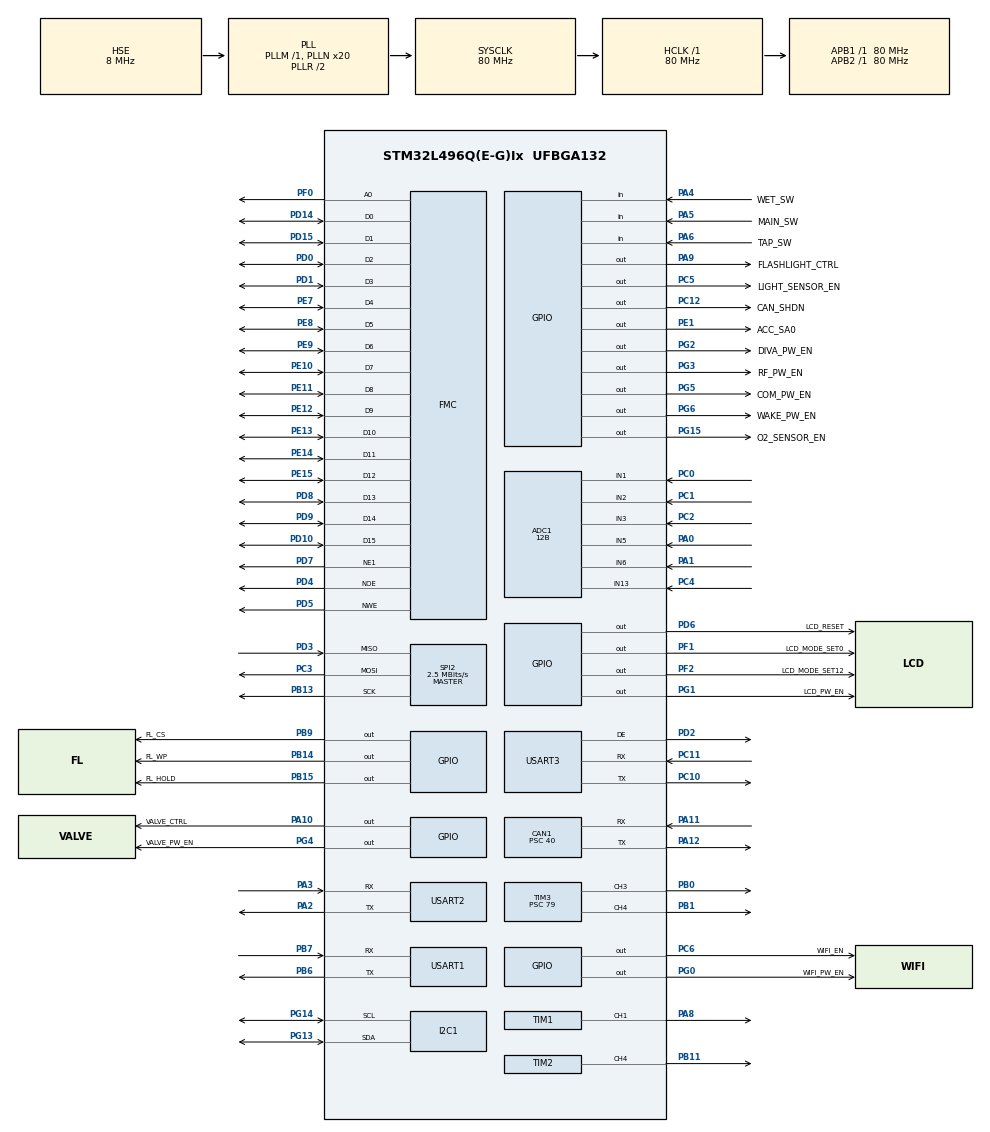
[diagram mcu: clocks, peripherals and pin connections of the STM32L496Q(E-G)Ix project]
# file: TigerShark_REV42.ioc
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ADC1.Channel-0\#ChannelRegularConversion=ADC_CHANNEL_1
ADC1.Channel-1\#ChannelRegularConversion=ADC_CHANNEL_2
ADC1.Channel-2\#ChannelRegularConversion=ADC_CHANNEL_3
ADC1.Channel-3\#ChannelRegularConversion=ADC_CHANNEL_5
ADC1.Channel-4\#ChannelRegularConversion=ADC_CHANNEL_6
ADC1.Channel-5\#ChannelRegularConversion=ADC_CHANNEL_13
ADC1.Channel-6\#ChannelRegularConversion=ADC_CHANNEL_VREFINT
ADC1.ClockPrescaler=ADC_CLOCK_ASYNC_DIV1
ADC1.ContinuousConvMode=DISABLE
ADC1.DMAContinuousRequests=ENABLE
ADC1.DataAlign=ADC_DATAALIGN_RIGHT
ADC1.EOCSelection=ADC_EOC_SINGLE_CONV
ADC1.ExternalTrigConv=ADC_EXTERNALTRIG_T4_TRGO
ADC1.NbrOfConversion=7
ADC1.NbrOfConversionFlag=1
ADC1.OffsetNumber-0\#ChannelRegularConversion=ADC_OFFSET_NONE
ADC1.OffsetNumber-1\#ChannelRegularConversion=ADC_OFFSET_NONE
ADC1.OffsetNumber-2\#ChannelRegularConversion=ADC_OFFSET_NONE
ADC1.OffsetNumber-3\#ChannelRegularConversion=ADC_OFFSET_NONE
ADC1.OffsetNumber-4\#ChannelRegularConversion=ADC_OFFSET_NONE
ADC1.OffsetNumber-5\#ChannelRegularConversion=ADC_OFFSET_NONE
ADC1.OffsetNumber-6\#ChannelRegularConversion=ADC_OFFSET_NONE
ADC1.OversamplingMode=DISABLE
ADC1.Rank-0\#ChannelRegularConversion=1
ADC1.Rank-1\#ChannelRegularConversion=2
ADC1.Rank-2\#ChannelRegularConversion=3
ADC1.Rank-3\#ChannelRegularConversion=4
ADC1.Rank-4\#ChannelRegularConversion=5
ADC1.Rank-5\#ChannelRegularConversion=6
ADC1.Rank-6\#ChannelRegularConversion=7
ADC1.Resolution=ADC_RESOLUTION_12B
ADC1.SamplingTime-0\#ChannelRegularConversion=ADC_SAMPLETIME_92CYCLES_5
ADC1.SamplingTime-1\#ChannelRegularConversion=ADC_SAMPLETIME_92CYCLES_5
ADC1.SamplingTime-2\#ChannelRegularConversion=ADC_SAMPLETIME_92CYCLES_5
ADC1.SamplingTime-3\#ChannelRegularConversion=ADC_SAMPLETIME_92CYCLES_5
ADC1.SamplingTime-4\#ChannelRegularConversion=ADC_SAMPLETIME_92CYCLES_5
ADC1.SamplingTime-5\#ChannelRegularConversion=ADC_SAMPLETIME_92CYCLES_5
ADC1.SamplingTime-6\#ChannelRegularConversion=ADC_SAMPLETIME_92CYCLES_5
ADC1.master=1
CAN1.BS1=CAN_BS1_13TQ
CAN1.BS2=CAN_BS2_2TQ
CAN1.CalculateBaudRate=125000
CAN1.CalculateTimeBit=8000
CAN1.CalculateTimeQuantum=500.0
CAN1.Prescaler=40
CAN1.SJW=CAN_SJW_4TQ
Dma.ADC1.0.Direction=DMA_PERIPH_TO_MEMORY
Dma.ADC1.0.Instance=DMA1_Channel1
Dma.ADC1.0.MemDataAlignment=DMA_MDATAALIGN_HALFWORD
Dma.ADC1.0.MemInc=DMA_MINC_ENABLE
Dma.ADC1.0.Mode=DMA_CIRCULAR
Dma.ADC1.0.PeriphDataAlignment=DMA_PDATAALIGN_HALFWORD
Dma.ADC1.0.PeriphInc=DMA_PINC_DISABLE
Dma.ADC1.0.Priority=DMA_PRIORITY_LOW
Dma.Request0=ADC1
FMC.AddressSetupTime1=0
FMC.BusTurnAroundDuration1=3
FMC.DataSetupTime1=1
FREERTOS.Tasks01=defaultTask,24,128,StartDefaultTask,Default,NULL,Dynamic,NULL,NULL
FREERTOS.configTOTAL_HEAP_SIZE=65535
FREERTOS.configUSE_NEWLIB_REENTRANT=1
I2C1.Speed=100
I2C1.Timing=0x10D19CE4
Mcu.Family=STM32L4
Mcu.Name=STM32L496Q(E-G)Ix
Mcu.Package=UFBGA132
NVIC.ADC1_2_IRQn=true\:5\:0\:true\:false\:true\:true\:true\:true\:true
NVIC.CAN1_RX0_IRQn=true\:5\:0\:true\:false\:true\:true\:true\:true\:true
NVIC.CAN1_RX1_IRQn=true\:5\:0\:true\:false\:true\:true\:true\:true\:true
NVIC.DMA1_Channel1_IRQn=true\:5\:0\:false\:false\:true\:true\:false\:true\:true
NVIC.PriorityGroup=NVIC_PRIORITYGROUP_4
NVIC.TIM1_TRG_COM_TIM17_IRQn=true\:5\:0\:false\:false\:true\:true\:true\:true\:true
NVIC.TIM1_UP_TIM16_IRQn=true\:15\:0\:false\:false\:true\:false\:false\:true\:true
NVIC.TIM6_DAC_IRQn=true\:5\:0\:false\:false\:true\:true\:true\:true\:true
NVIC.TimeBase=TIM1_UP_TIM16_IRQn
NVIC.TimeBaseIP=TIM16
NVIC.USART1_IRQn=true\:5\:0\:false\:false\:true\:true\:true\:true\:true
NVIC.USART2_IRQn=true\:5\:0\:false\:false\:true\:true\:true\:true\:true
PA0.Signal=ADCx_IN5
PA1.Signal=ADCx_IN6
PA10.GPIO_Label=VALVE_CTRL
PA10.GPIO_ModeDefaultOutputPP=GPIO_MODE_OUTPUT_PP
PA10.GPIO_PuPd=GPIO_PULLUP
PA10.GPIO_Speed=GPIO_SPEED_FREQ_VERY_HIGH
PA10.PinState=GPIO_PIN_SET
PA10.Signal=GPIO_Output
PA11.Mode=CAN_Activate
PA11.Signal=CAN1_RX
PA12.Mode=CAN_Activate
PA12.Signal=CAN1_TX
PA13\ (JTMS/SWDIO).Mode=Serial_Wire
PA13\ (JTMS/SWDIO).Signal=SYS_JTMS-SWDIO
PA14\ (JTCK/SWCLK).Mode=Serial_Wire
PA14\ (JTCK/SWCLK).Signal=SYS_JTCK-SWCLK
PA2.Mode=Asynchronous
PA2.Signal=USART2_TX
PA3.Mode=Asynchronous
PA3.Signal=USART2_RX
PA4.GPIO_Label=WET_SW
PA4.GPIO_PuPd=GPIO_NOPULL
PA4.Signal=GPIO_Input
PA5.GPIO_Label=MAIN_SW
PA5.GPIO_PuPd=GPIO_NOPULL
PA5.Signal=GPIO_Input
PA6.GPIO_Label=TAP_SW
PA6.GPIO_PuPd=GPIO_NOPULL
PA6.Signal=GPIO_Input
PA8.Signal=S_TIM1_CH1
PA9.GPIO_Label=FLASHLIGHT_CTRL
PA9.Signal=GPIO_Output
PB0.Signal=S_TIM3_CH3
PB1.Signal=S_TIM3_CH4
PB11.Signal=S_TIM2_CH4
PB13.Mode=Full_Duplex_Master
PB13.Signal=SPI2_SCK
PB14.GPIO_Label=FL_WP
PB14.GPIO_ModeDefaultOutputPP=GPIO_MODE_OUTPUT_PP
PB14.GPIO_PuPd=GPIO_PULLUP
PB14.GPIO_Speed=GPIO_SPEED_FREQ_LOW
PB14.PinState=GPIO_PIN_SET
PB14.Signal=GPIO_Output
PB15.GPIO_Label=FL_HOLD
PB15.GPIO_ModeDefaultOutputPP=GPIO_MODE_OUTPUT_PP
PB15.GPIO_PuPd=GPIO_PULLUP
PB15.PinState=GPIO_PIN_SET
PB15.Signal=GPIO_Output
PB6.Mode=Asynchronous
PB6.Signal=USART1_TX
PB7.Mode=Asynchronous
PB7.Signal=USART1_RX
PB9.GPIO_Label=FL_CS
PB9.GPIO_ModeDefaultOutputPP=GPIO_MODE_OUTPUT_PP
PB9.GPIO_PuPd=GPIO_PULLUP
PB9.GPIO_Speed=GPIO_SPEED_FREQ_LOW
PB9.PinState=GPIO_PIN_SET
PB9.Signal=GPIO_Output
PC0.Signal=ADCx_IN1
PC1.Signal=ADCx_IN2
PC10.Mode=Asynchronous
PC10.Signal=USART3_TX
PC11.Mode=Asynchronous
PC11.Signal=USART3_RX
PC12.GPIO_Label=CAN_SHDN
PC12.GPIO_ModeDefaultOutputPP=GPIO_MODE_OUTPUT_PP
PC12.GPIO_PuPd=GPIO_PULLUP
PC12.Signal=GPIO_Output
PC14-OSC32_IN\ (PC14).Mode=LSE-External-Oscillator
PC14-OSC32_IN\ (PC14).Signal=RCC_OSC32_IN
PC15-OSC32_OUT\ (PC15).Mode=LSE-External-Oscillator
PC15-OSC32_OUT\ (PC15).Signal=RCC_OSC32_OUT
PC2.Signal=ADCx_IN3
PC3.Mode=Full_Duplex_Master
PC3.Signal=SPI2_MOSI
PC4.Signal=ADCx_IN13
PC5.GPIO_Label=LIGHT_SENSOR_EN
PC5.GPIO_PuPd=GPIO_PULLUP
PC5.Signal=GPIO_Output
PC6.GPIO_Label=WIFI_EN
PC6.GPIO_ModeDefaultOutputPP=GPIO_MODE_OUTPUT_PP
PC6.GPIO_PuPd=GPIO_PULLUP
PC6.Signal=GPIO_Output
PD0.Signal=FMC_D2_DA2
PD1.Signal=FMC_D3_DA3
PD10.Signal=FMC_D15_DA15
PD14.Signal=FMC_D0_DA0
PD15.Signal=FMC_D1_DA1
PD2.Mode=Hardware Flow Control (RS485)
PD2.Signal=USART3_DE
PD3.Mode=Full_Duplex_Master
PD3.Signal=SPI2_MISO
PD4.Signal=FMC_NOE
PD5.Signal=FMC_NWE
PD6.GPIO_Label=LCD_RESET
PD6.GPIO_PuPd=GPIO_PULLUP
PD6.PinState=GPIO_PIN_SET
PD6.Signal=GPIO_Output
PD7.Mode=NorPsramChipSelect1_1
PD7.Signal=FMC_NE1
PD8.Signal=FMC_D13_DA13
PD9.Signal=FMC_D14_DA14
PE1.GPIO_Label=ACC_SA0
PE1.GPIO_PuPd=GPIO_PULLUP
PE1.Signal=GPIO_Output
PE10.Signal=FMC_D7_DA7
PE11.Signal=FMC_D8_DA8
PE12.Signal=FMC_D9_DA9
PE13.Signal=FMC_D10_DA10
PE14.Signal=FMC_D11_DA11
PE15.Signal=FMC_D12_DA12
PE7.Signal=FMC_D4_DA4
PE8.Signal=FMC_D5_DA5
PE9.Signal=FMC_D6_DA6
PF0.Signal=FMC_A0
PF1.GPIO_Label=LCD_MODE_SET0
PF1.GPIO_ModeDefaultOutputPP=GPIO_MODE_OUTPUT_PP
PF1.GPIO_PuPd=GPIO_PULLUP
PF1.PinState=GPIO_PIN_SET
PF1.Signal=GPIO_Output
PF2.GPIO_Label=LCD_MODE_SET12
PF2.GPIO_PuPd=GPIO_PULLDOWN
PF2.Signal=GPIO_Output
PG0.GPIO_Label=WIFI_PW_EN
PG0.Signal=GPIO_Output
PG1.GPIO_Label=LCD_PW_EN
PG1.Signal=GPIO_Output
PG13.Mode=I2C
PG13.Signal=I2C1_SDA
PG14.Mode=I2C
PG14.Signal=I2C1_SCL
PG15.GPIO_Label=O2_SENSOR_EN
PG15.Signal=GPIO_Output
PG2.GPIO_Label=DIVA_PW_EN
PG2.Signal=GPIO_Output
PG3.GPIO_Label=RF_PW_EN
PG3.Signal=GPIO_Output
PG4.GPIO_Label=VALVE_PW_EN
PG4.Signal=GPIO_Output
PG5.GPIO_Label=COM_PW_EN
PG5.Signal=GPIO_Output
PG6.GPIO_Label=WAKE_PW_EN
PG6.Signal=GPIO_Output
PH0-OSC_IN\ (PH0).Mode=HSE-External-Oscillator
PH0-OSC_IN\ (PH0).Signal=RCC_OSC_IN
PH1-OSC_OUT\ (PH1).Mode=HSE-External-Oscillator
PH1-OSC_OUT\ (PH1).Signal=RCC_OSC_OUT
ProjectManager.HeapSize=0x400
ProjectManager.StackSize=0x1024
ProjectManager.TargetToolchain=STM32CubeIDE
RCC.ADCFreq_Value=32000000
RCC.AHBFreq_Value=80000000
RCC.APB1Freq_Value=80000000
RCC.APB1TimFreq_Value=80000000
RCC.APB2Freq_Value=80000000
RCC.APB2TimFreq_Value=80000000
RCC.CortexFreq_Value=80000000
RCC.HCLKFreq_Value=80000000
RCC.HSE_VALUE=8000000
RCC.HSI48_VALUE=48000000
RCC.HSI_VALUE=16000000
RCC.MSI_VALUE=4000000
RCC.PLLN=20
RCC.PLLSourceVirtual=RCC_PLLSOURCE_HSE
RCC.RTCClockSelection=RCC_RTCCLKSOURCE_LSE
RCC.SYSCLKFreq_VALUE=80000000
RCC.SYSCLKSource=RCC_SYSCLKSOURCE_PLLCLK
RCC.USBFreq_Value=32000000
RCC.VCOOutputFreq_Value=160000000
RTC.Date=1
RTC.Month=RTC_MONTH_JANUARY
RTC.Year=0
SH.ADCx_IN1.0=ADC1_IN1,IN1-Single-Ended
SH.ADCx_IN13.0=ADC1_IN13,IN13-Single-Ended
SH.ADCx_IN2.0=ADC1_IN2,IN2-Single-Ended
SH.ADCx_IN3.0=ADC1_IN3,IN3-Single-Ended
SH.ADCx_IN5.0=ADC1_IN5,IN5-Single-Ended
SH.ADCx_IN6.0=ADC1_IN6,IN6-Single-Ended
SH.FMC_A0.0=FMC_A0,A0_1
SH.FMC_D0_DA0.0=FMC_D0,16b-d1
SH.FMC_D10_DA10.0=FMC_D10,16b-d1
SH.FMC_D11_DA11.0=FMC_D11,16b-d1
SH.FMC_D12_DA12.0=FMC_D12,16b-d1
SH.FMC_D13_DA13.0=FMC_D13,16b-d1
SH.FMC_D14_DA14.0=FMC_D14,16b-d1
SH.FMC_D15_DA15.0=FMC_D15,16b-d1
SH.FMC_D1_DA1.0=FMC_D1,16b-d1
SH.FMC_D2_DA2.0=FMC_D2,16b-d1
SH.FMC_D3_DA3.0=FMC_D3,16b-d1
SH.FMC_D4_DA4.0=FMC_D4,16b-d1
SH.FMC_D5_DA5.0=FMC_D5,16b-d1
SH.FMC_D6_DA6.0=FMC_D6,16b-d1
SH.FMC_D7_DA7.0=FMC_D7,16b-d1
SH.FMC_D8_DA8.0=FMC_D8,16b-d1
SH.FMC_D9_DA9.0=FMC_D9,16b-d1
SH.FMC_NOE.0=FMC_NOE,Lcd1
SH.FMC_NWE.0=FMC_NWE,Lcd1
SH.S_TIM1_CH1.0=TIM1_CH1,PWM Generation1 CH1
SH.S_TIM2_CH4.0=TIM2_CH4,PWM Generation4 CH4
SH.S_TIM3_CH3.0=TIM3_CH3,PWM Generation3 CH3
SH.S_TIM3_CH4.0=TIM3_CH4,PWM Generation4 CH4
SPI2.BaudRatePrescaler=SPI_BAUDRATEPRESCALER_32
SPI2.CalculateBaudRate=2.5 MBits/s
SPI2.DataSize=SPI_DATASIZE_8BIT
SPI2.Direction=SPI_DIRECTION_2LINES
SPI2.Mode=SPI_MODE_MASTER
SPI2.VirtualType=VM_MASTER
TIM1.Channel-PWM\ Generation1\ CH1=TIM_CHANNEL_1
TIM1.Period=499
TIM1.Prescaler=79
TIM1.Pulse-PWM\ Generation1\ CH1=100
TIM2.Channel-PWM\ Generation4\ CH4=TIM_CHANNEL_4
TIM2.OCPolarity_4=TIM_OCPOLARITY_HIGH
TIM2.Period=1000
TIM2.Prescaler=79
TIM3.Channel-PWM\ Generation3\ CH3=TIM_CHANNEL_3
TIM3.Channel-PWM\ Generation4\ CH4=TIM_CHANNEL_4
TIM3.OCMode_PWM-PWM\ Generation4\ CH4=TIM_OCMODE_PWM1
TIM3.OCPolarity_3=TIM_OCPOLARITY_HIGH
TIM3.OCPolarity_4=TIM_OCPOLARITY_HIGH
TIM3.Period=1000
TIM3.Prescaler=79
TIM3.Pulse-PWM\ Generation3\ CH3=0
TIM3.Pulse-PWM\ Generation4\ CH4=0
TIM4.Channel-Output\ Compare1\ No\ Output=TIM_CHANNEL_1
TIM4.Period=625
TIM4.Prescaler=79
TIM4.TIM_MasterOutputTrigger=TIM_TRGO_UPDATE
TIM6.AutoReloadPreload=TIM_AUTORELOAD_PRELOAD_ENABLE
TIM6.Period=7999
TIM6.Prescaler=9999
USART1.VirtualMode-Asynchronous=VM_ASYNC
USART2.Parity=PARITY_NONE
USART2.VirtualMode-Asynchronous=VM_ASYNC
USART2.WordLength=WORDLENGTH_8B
USART3.VirtualMode-Asynchronous=VM_ASYNC
USART3.VirtualMode-Hardware\ Flow\ Control\ (RS485)=VM_ASYNC
VP_ADC1_Vref_Input.Mode=IN-Vrefint
VP_FREERTOS_VS_CMSIS_V2.Mode=CMSIS_V2
VP_RTC_VS_RTC_Activate.Mode=RTC_Enabled
VP_RTC_VS_RTC_Calendar.Mode=RTC_Calendar
VP_SYS_VS_tim16.Mode=TIM16
VP_TIM3_VS_ClockSourceINT.Mode=Internal
VP_TIM4_VS_no_output1.Mode=Output Compare1 No Output
VP_TIM6_VS_ClockSourceINT.Mode=Enable_Timer
board=custom

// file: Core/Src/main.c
/* USER CODE BEGIN Header */
/**
  ******************************************************************************
  * @file           : main.c
  * @brief          : Main program body
  ******************************************************************************
  * @attention
  *
  * Copyright (c) 2025 STMicroelectronics.
  * All rights reserved.
  *
  * This software is licensed under terms that can be found in the LICENSE file
  * in the root directory of this software component.
  * If no LICENSE file comes with this software, it is provided AS-IS.
  *
  ******************************************************************************
  */
/* USER CODE END Header */
#include "main.h"
#include "cmsis_os2.h"

/* USER CODE BEGIN Includes */
#include "app_main.h"
/* USER CODE END Includes */

/* USER CODE BEGIN PTD */
#define ETX_APP_FLASH_ADDR    (0x0800A000)
/* USER CODE END PTD */

ADC_HandleTypeDef hadc1;
DMA_HandleTypeDef hdma_adc1;

CAN_HandleTypeDef hcan1;

I2C_HandleTypeDef hi2c1;

RTC_HandleTypeDef hrtc;

SPI_HandleTypeDef hspi2;

TIM_HandleTypeDef htim1;
TIM_HandleTypeDef htim2;
TIM_HandleTypeDef htim3;
TIM_HandleTypeDef htim4;
TIM_HandleTypeDef htim6;

UART_HandleTypeDef huart1;
UART_HandleTypeDef huart2;
UART_HandleTypeDef huart3;

SRAM_HandleTypeDef hsram1;

/* Definitions for defaultTask */
osThreadId_t defaultTaskHandle;
const osThreadAttr_t defaultTask_attributes = {
  .name = "defaultTask",
  .stack_size = 128 * 4,
  .priority = (osPriority_t) osPriorityNormal,
};

void SystemClock_Config(void);
static void MX_GPIO_Init(void);
static void MX_DMA_Init(void);
static void MX_ADC1_Init(void);
static void MX_TIM3_Init(void);
static void MX_FMC_Init(void);
static void MX_I2C1_Init(void);
static void MX_SPI2_Init(void);
static void MX_TIM4_Init(void);
static void MX_TIM1_Init(void);
static void MX_TIM2_Init(void);
static void MX_USART3_UART_Init(void);
static void MX_CAN1_Init(void);
static void MX_USART2_UART_Init(void);
static void MX_USART1_UART_Init(void);
static void MX_TIM6_Init(void);
static void MX_RTC_Init(void);
void StartDefaultTask(void *argument);

int main(void)
{

  /* USER CODE BEGIN 1 */
  SCB->VTOR = (uint32_t) ETX_APP_FLASH_ADDR;
  /* USER CODE END 1 */

  /* MCU Configuration--------------------------------------------------------*/

  /* Reset of all peripherals, Initializes the Flash interface and the Systick. */
  HAL_Init();

  /* Configure the system clock */
  SystemClock_Config();

  /* Initialize all configured peripherals */
  MX_GPIO_Init();
  MX_DMA_Init();
  MX_ADC1_Init();
  MX_TIM3_Init();
  MX_FMC_Init();
  MX_I2C1_Init();
  MX_SPI2_Init();
  MX_TIM4_Init();
  MX_TIM1_Init();
  MX_TIM2_Init();
  MX_USART3_UART_Init();
  MX_CAN1_Init();
  MX_USART2_UART_Init();
  MX_USART1_UART_Init();
  MX_TIM6_Init();
  MX_RTC_Init();
  /* USER CODE BEGIN 2 */
  app_main_init();
  /* USER CODE END 2 */

  /* Init scheduler */
  osKernelInitialize();

  /* Create the thread(s) */
  /* creation of defaultTask */
  defaultTaskHandle = osThreadNew(StartDefaultTask, NULL, &defaultTask_attributes);

  /* Start scheduler */
  osKernelStart();

  /* We should never get here as control is now taken by the scheduler */

  /* Infinite loop */
  while (1)
  {

  }
}

void SystemClock_Config(void)
{
  RCC_OscInitTypeDef RCC_OscInitStruct = {0};
  RCC_ClkInitTypeDef RCC_ClkInitStruct = {0};

  /** Configure the main internal regulator output voltage
  */
  if (HAL_PWREx_ControlVoltageScaling(PWR_REGULATOR_VOLTAGE_SCALE1) != HAL_OK)
  {
    Error_Handler();
  }

  /** Configure LSE Drive Capability
  */
  HAL_PWR_EnableBkUpAccess();
  __HAL_RCC_LSEDRIVE_CONFIG(RCC_LSEDRIVE_LOW);

  /** Initializes the RCC Oscillators according to the specified parameters
  * in the RCC_OscInitTypeDef structure.
  */
  RCC_OscInitStruct.OscillatorType = RCC_OSCILLATORTYPE_HSE|RCC_OSCILLATORTYPE_LSE;
  RCC_OscInitStruct.HSEState = RCC_HSE_ON;
  RCC_OscInitStruct.LSEState = RCC_LSE_ON;
  RCC_OscInitStruct.PLL.PLLState = RCC_PLL_ON;
  RCC_OscInitStruct.PLL.PLLSource = RCC_PLLSOURCE_HSE;
  RCC_OscInitStruct.PLL.PLLM = 1;
  RCC_OscInitStruct.PLL.PLLN = 20;
  RCC_OscInitStruct.PLL.PLLP = RCC_PLLP_DIV2;
  RCC_OscInitStruct.PLL.PLLQ = RCC_PLLQ_DIV2;
  RCC_OscInitStruct.PLL.PLLR = RCC_PLLR_DIV2;
  if (HAL_RCC_OscConfig(&RCC_OscInitStruct) != HAL_OK)
  {
    Error_Handler();
  }

  /** Initializes the CPU, AHB and APB buses clocks
  */
  RCC_ClkInitStruct.ClockType = RCC_CLOCKTYPE_HCLK|RCC_CLOCKTYPE_SYSCLK
                              |RCC_CLOCKTYPE_PCLK1|RCC_CLOCKTYPE_PCLK2;
  RCC_ClkInitStruct.SYSCLKSource = RCC_SYSCLKSOURCE_PLLCLK;
  RCC_ClkInitStruct.AHBCLKDivider = RCC_SYSCLK_DIV1;
  RCC_ClkInitStruct.APB1CLKDivider = RCC_HCLK_DIV1;
  RCC_ClkInitStruct.APB2CLKDivider = RCC_HCLK_DIV1;

  if (HAL_RCC_ClockConfig(&RCC_ClkInitStruct, FLASH_LATENCY_4) != HAL_OK)
  {
    Error_Handler();
  }
}

static void MX_ADC1_Init(void)
{

  ADC_MultiModeTypeDef multimode = {0};
  ADC_ChannelConfTypeDef sConfig = {0};

  /** Common config
  */
  hadc1.Instance = ADC1;
  hadc1.Init.ClockPrescaler = ADC_CLOCK_ASYNC_DIV1;
  hadc1.Init.Resolution = ADC_RESOLUTION_12B;
  hadc1.Init.DataAlign = ADC_DATAALIGN_RIGHT;
  hadc1.Init.ScanConvMode = ADC_SCAN_ENABLE;
  hadc1.Init.EOCSelection = ADC_EOC_SINGLE_CONV;
  hadc1.Init.LowPowerAutoWait = DISABLE;
  hadc1.Init.ContinuousConvMode = DISABLE;
  hadc1.Init.NbrOfConversion = 7;
  hadc1.Init.DiscontinuousConvMode = DISABLE;
  hadc1.Init.ExternalTrigConv = ADC_EXTERNALTRIG_T4_TRGO;
  hadc1.Init.ExternalTrigConvEdge = ADC_EXTERNALTRIGCONVEDGE_RISING;
  hadc1.Init.DMAContinuousRequests = ENABLE;
  hadc1.Init.Overrun = ADC_OVR_DATA_PRESERVED;
  hadc1.Init.OversamplingMode = DISABLE;
  if (HAL_ADC_Init(&hadc1) != HAL_OK)
  {
    Error_Handler();
  }

  /** Configure the ADC multi-mode
  */
  multimode.Mode = ADC_MODE_INDEPENDENT;
  if (HAL_ADCEx_MultiModeConfigChannel(&hadc1, &multimode) != HAL_OK)
  {
    Error_Handler();
  }

  /** Configure Regular Channel
  */
  sConfig.Channel = ADC_CHANNEL_1;
  sConfig.Rank = ADC_REGULAR_RANK_1;
  sConfig.SamplingTime = ADC_SAMPLETIME_92CYCLES_5;
  sConfig.SingleDiff = ADC_SINGLE_ENDED;
  sConfig.OffsetNumber = ADC_OFFSET_NONE;
  sConfig.Offset = 0;
  if (HAL_ADC_ConfigChannel(&hadc1, &sConfig) != HAL_OK)
  {
    Error_Handler();
  }

  /** Configure Regular Channel
  */
  sConfig.Channel = ADC_CHANNEL_2;
  sConfig.Rank = ADC_REGULAR_RANK_2;
  if (HAL_ADC_ConfigChannel(&hadc1, &sConfig) != HAL_OK)
  {
    Error_Handler();
  }

  /** Configure Regular Channel
  */
  sConfig.Channel = ADC_CHANNEL_3;
  sConfig.Rank = ADC_REGULAR_RANK_3;
  if (HAL_ADC_ConfigChannel(&hadc1, &sConfig) != HAL_OK)
  {
    Error_Handler();
  }

  /** Configure Regular Channel
  */
  sConfig.Channel = ADC_CHANNEL_5;
  sConfig.Rank = ADC_REGULAR_RANK_4;
  if (HAL_ADC_ConfigChannel(&hadc1, &sConfig) != HAL_OK)
  {
    Error_Handler();
  }

  /** Configure Regular Channel
  */
  sConfig.Channel = ADC_CHANNEL_6;
  sConfig.Rank = ADC_REGULAR_RANK_5;
  if (HAL_ADC_ConfigChannel(&hadc1, &sConfig) != HAL_OK)
  {
    Error_Handler();
  }

  /** Configure Regular Channel
  */
  sConfig.Channel = ADC_CHANNEL_13;
  sConfig.Rank = ADC_REGULAR_RANK_6;
  if (HAL_ADC_ConfigChannel(&hadc1, &sConfig) != HAL_OK)
  {
    Error_Handler();
  }

  /** Configure Regular Channel
  */
  sConfig.Channel = ADC_CHANNEL_VREFINT;
  sConfig.Rank = ADC_REGULAR_RANK_7;
  if (HAL_ADC_ConfigChannel(&hadc1, &sConfig) != HAL_OK)
  {
    Error_Handler();
  }

}

static void MX_CAN1_Init(void)
{

  hcan1.Instance = CAN1;
  hcan1.Init.Prescaler = 40;
  hcan1.Init.Mode = CAN_MODE_NORMAL;
  hcan1.Init.SyncJumpWidth = CAN_SJW_4TQ;
  hcan1.Init.TimeSeg1 = CAN_BS1_13TQ;
  hcan1.Init.TimeSeg2 = CAN_BS2_2TQ;
  hcan1.Init.TimeTriggeredMode = DISABLE;
  hcan1.Init.AutoBusOff = DISABLE;
  hcan1.Init.AutoWakeUp = DISABLE;
  hcan1.Init.AutoRetransmission = DISABLE;
  hcan1.Init.ReceiveFifoLocked = DISABLE;
  hcan1.Init.TransmitFifoPriority = DISABLE;
  if (HAL_CAN_Init(&hcan1) != HAL_OK)
  {
    Error_Handler();
  }

}

static void MX_I2C1_Init(void)
{

  hi2c1.Instance = I2C1;
  hi2c1.Init.Timing = 0x10D19CE4;
  hi2c1.Init.OwnAddress1 = 0;
  hi2c1.Init.AddressingMode = I2C_ADDRESSINGMODE_7BIT;
  hi2c1.Init.DualAddressMode = I2C_DUALADDRESS_DISABLE;
  hi2c1.Init.OwnAddress2 = 0;
  hi2c1.Init.OwnAddress2Masks = I2C_OA2_NOMASK;
  hi2c1.Init.GeneralCallMode = I2C_GENERALCALL_DISABLE;
  hi2c1.Init.NoStretchMode = I2C_NOSTRETCH_DISABLE;
  if (HAL_I2C_Init(&hi2c1) != HAL_OK)
  {
    Error_Handler();
  }

  /** Configure Analogue filter
  */
  if (HAL_I2CEx_ConfigAnalogFilter(&hi2c1, I2C_ANALOGFILTER_ENABLE) != HAL_OK)
  {
    Error_Handler();
  }

  /** Configure Digital filter
  */
  if (HAL_I2CEx_ConfigDigitalFilter(&hi2c1, 0) != HAL_OK)
  {
    Error_Handler();
  }

}

static void MX_RTC_Init(void)
{

  RTC_TimeTypeDef sTime = {0};
  RTC_DateTypeDef sDate = {0};

  /** Initialize RTC Only
  */
  hrtc.Instance = RTC;
  hrtc.Init.HourFormat = RTC_HOURFORMAT_24;
  hrtc.Init.AsynchPrediv = 127;
  hrtc.Init.SynchPrediv = 255;
  hrtc.Init.OutPut = RTC_OUTPUT_DISABLE;
  hrtc.Init.OutPutRemap = RTC_OUTPUT_REMAP_NONE;
  hrtc.Init.OutPutPolarity = RTC_OUTPUT_POLARITY_HIGH;
  hrtc.Init.OutPutType = RTC_OUTPUT_TYPE_OPENDRAIN;
  if (HAL_RTC_Init(&hrtc) != HAL_OK)
  {
    Error_Handler();
  }

  /** Initialize RTC and set the Time and Date
  */
  sTime.Hours = 0x0;
  sTime.Minutes = 0x0;
  sTime.Seconds = 0x0;
  sTime.DayLightSaving = RTC_DAYLIGHTSAVING_NONE;
  sTime.StoreOperation = RTC_STOREOPERATION_RESET;
  if (HAL_RTC_SetTime(&hrtc, &sTime, RTC_FORMAT_BCD) != HAL_OK)
  {
    Error_Handler();
  }
  sDate.WeekDay = RTC_WEEKDAY_MONDAY;
  sDate.Month = RTC_MONTH_JANUARY;
  sDate.Date = 0x1;
  sDate.Year = 0x0;

  if (HAL_RTC_SetDate(&hrtc, &sDate, RTC_FORMAT_BCD) != HAL_OK)
  {
    Error_Handler();
  }

}

static void MX_SPI2_Init(void)
{

  /* SPI2 parameter configuration*/
  hspi2.Instance = SPI2;
  hspi2.Init.Mode = SPI_MODE_MASTER;
  hspi2.Init.Direction = SPI_DIRECTION_2LINES;
  hspi2.Init.DataSize = SPI_DATASIZE_8BIT;
  hspi2.Init.CLKPolarity = SPI_POLARITY_LOW;
  hspi2.Init.CLKPhase = SPI_PHASE_1EDGE;
  hspi2.Init.NSS = SPI_NSS_SOFT;
  hspi2.Init.BaudRatePrescaler = SPI_BAUDRATEPRESCALER_32;
  hspi2.Init.FirstBit = SPI_FIRSTBIT_MSB;
  hspi2.Init.TIMode = SPI_TIMODE_DISABLE;
  hspi2.Init.CRCCalculation = SPI_CRCCALCULATION_DISABLE;
  hspi2.Init.CRCPolynomial = 7;
  hspi2.Init.CRCLength = SPI_CRC_LENGTH_DATASIZE;
  hspi2.Init.NSSPMode = SPI_NSS_PULSE_ENABLE;
  if (HAL_SPI_Init(&hspi2) != HAL_OK)
  {
    Error_Handler();
  }

}

static void MX_TIM1_Init(void)
{

  TIM_MasterConfigTypeDef sMasterConfig = {0};
  TIM_OC_InitTypeDef sConfigOC = {0};
  TIM_BreakDeadTimeConfigTypeDef sBreakDeadTimeConfig = {0};

  htim1.Instance = TIM1;
  htim1.Init.Prescaler = 79;
  htim1.Init.CounterMode = TIM_COUNTERMODE_UP;
  htim1.Init.Period = 499;
  htim1.Init.ClockDivision = TIM_CLOCKDIVISION_DIV1;
  htim1.Init.RepetitionCounter = 0;
  htim1.Init.AutoReloadPreload = TIM_AUTORELOAD_PRELOAD_DISABLE;
  if (HAL_TIM_PWM_Init(&htim1) != HAL_OK)
  {
    Error_Handler();
  }
  sMasterConfig.MasterOutputTrigger = TIM_TRGO_RESET;
  sMasterConfig.MasterOutputTrigger2 = TIM_TRGO2_RESET;
  sMasterConfig.MasterSlaveMode = TIM_MASTERSLAVEMODE_DISABLE;
  if (HAL_TIMEx_MasterConfigSynchronization(&htim1, &sMasterConfig) != HAL_OK)
  {
    Error_Handler();
  }
  sConfigOC.OCMode = TIM_OCMODE_PWM1;
  sConfigOC.Pulse = 100;
  sConfigOC.OCPolarity = TIM_OCPOLARITY_HIGH;
  sConfigOC.OCNPolarity = TIM_OCNPOLARITY_HIGH;
  sConfigOC.OCFastMode = TIM_OCFAST_DISABLE;
  sConfigOC.OCIdleState = TIM_OCIDLESTATE_RESET;
  sConfigOC.OCNIdleState = TIM_OCNIDLESTATE_RESET;
  if (HAL_TIM_PWM_ConfigChannel(&htim1, &sConfigOC, TIM_CHANNEL_1) != HAL_OK)
  {
    Error_Handler();
  }
  sBreakDeadTimeConfig.OffStateRunMode = TIM_OSSR_DISABLE;
  sBreakDeadTimeConfig.OffStateIDLEMode = TIM_OSSI_DISABLE;
  sBreakDeadTimeConfig.LockLevel = TIM_LOCKLEVEL_OFF;
  sBreakDeadTimeConfig.DeadTime = 0;
  sBreakDeadTimeConfig.BreakState = TIM_BREAK_DISABLE;
  sBreakDeadTimeConfig.BreakPolarity = TIM_BREAKPOLARITY_HIGH;
  sBreakDeadTimeConfig.BreakFilter = 0;
  sBreakDeadTimeConfig.Break2State = TIM_BREAK2_DISABLE;
  sBreakDeadTimeConfig.Break2Polarity = TIM_BREAK2POLARITY_HIGH;
  sBreakDeadTimeConfig.Break2Filter = 0;
  sBreakDeadTimeConfig.AutomaticOutput = TIM_AUTOMATICOUTPUT_DISABLE;
  if (HAL_TIMEx_ConfigBreakDeadTime(&htim1, &sBreakDeadTimeConfig) != HAL_OK)
  {
    Error_Handler();
  }
  HAL_TIM_MspPostInit(&htim1);

}

static void MX_TIM2_Init(void)
{

  TIM_MasterConfigTypeDef sMasterConfig = {0};
  TIM_OC_InitTypeDef sConfigOC = {0};

  htim2.Instance = TIM2;
  htim2.Init.Prescaler = 79;
  htim2.Init.CounterMode = TIM_COUNTERMODE_UP;
  htim2.Init.Period = 1000;
  htim2.Init.ClockDivision = TIM_CLOCKDIVISION_DIV1;
  htim2.Init.AutoReloadPreload = TIM_AUTORELOAD_PRELOAD_DISABLE;
  if (HAL_TIM_PWM_Init(&htim2) != HAL_OK)
  {
    Error_Handler();
  }
  sMasterConfig.MasterOutputTrigger = TIM_TRGO_RESET;
  sMasterConfig.MasterSlaveMode = TIM_MASTERSLAVEMODE_DISABLE;
  if (HAL_TIMEx_MasterConfigSynchronization(&htim2, &sMasterConfig) != HAL_OK)
  {
    Error_Handler();
  }
  sConfigOC.OCMode = TIM_OCMODE_PWM1;
  sConfigOC.Pulse = 0;
  sConfigOC.OCPolarity = TIM_OCPOLARITY_HIGH;
  sConfigOC.OCFastMode = TIM_OCFAST_DISABLE;
  if (HAL_TIM_PWM_ConfigChannel(&htim2, &sConfigOC, TIM_CHANNEL_4) != HAL_OK)
  {
    Error_Handler();
  }
  HAL_TIM_MspPostInit(&htim2);

}

static void MX_TIM3_Init(void)
{

  TIM_ClockConfigTypeDef sClockSourceConfig = {0};
  TIM_MasterConfigTypeDef sMasterConfig = {0};
  TIM_OC_InitTypeDef sConfigOC = {0};

  htim3.Instance = TIM3;
  htim3.Init.Prescaler = 79;
  htim3.Init.CounterMode = TIM_COUNTERMODE_UP;
  htim3.Init.Period = 1000;
  htim3.Init.ClockDivision = TIM_CLOCKDIVISION_DIV1;
  htim3.Init.AutoReloadPreload = TIM_AUTORELOAD_PRELOAD_DISABLE;
  if (HAL_TIM_Base_Init(&htim3) != HAL_OK)
  {
    Error_Handler();
  }
  sClockSourceConfig.ClockSource = TIM_CLOCKSOURCE_INTERNAL;
  if (HAL_TIM_ConfigClockSource(&htim3, &sClockSourceConfig) != HAL_OK)
  {
    Error_Handler();
  }
  if (HAL_TIM_PWM_Init(&htim3) != HAL_OK)
  {
    Error_Handler();
  }
  sMasterConfig.MasterOutputTrigger = TIM_TRGO_RESET;
  sMasterConfig.MasterSlaveMode = TIM_MASTERSLAVEMODE_DISABLE;
  if (HAL_TIMEx_MasterConfigSynchronization(&htim3, &sMasterConfig) != HAL_OK)
  {
    Error_Handler();
  }
  sConfigOC.OCMode = TIM_OCMODE_PWM1;
  sConfigOC.Pulse = 0;
  sConfigOC.OCPolarity = TIM_OCPOLARITY_HIGH;
  sConfigOC.OCFastMode = TIM_OCFAST_DISABLE;
  if (HAL_TIM_PWM_ConfigChannel(&htim3, &sConfigOC, TIM_CHANNEL_3) != HAL_OK)
  {
    Error_Handler();
  }
  if (HAL_TIM_PWM_ConfigChannel(&htim3, &sConfigOC, TIM_CHANNEL_4) != HAL_OK)
  {
    Error_Handler();
  }
  HAL_TIM_MspPostInit(&htim3);

}

static void MX_TIM4_Init(void)
{

  TIM_MasterConfigTypeDef sMasterConfig = {0};
  TIM_OC_InitTypeDef sConfigOC = {0};

  htim4.Instance = TIM4;
  htim4.Init.Prescaler = 79;
  htim4.Init.CounterMode = TIM_COUNTERMODE_UP;
  htim4.Init.Period = 625;
  htim4.Init.ClockDivision = TIM_CLOCKDIVISION_DIV1;
  htim4.Init.AutoReloadPreload = TIM_AUTORELOAD_PRELOAD_DISABLE;
  if (HAL_TIM_OC_Init(&htim4) != HAL_OK)
  {
    Error_Handler();
  }
  sMasterConfig.MasterOutputTrigger = TIM_TRGO_UPDATE;
  sMasterConfig.MasterSlaveMode = TIM_MASTERSLAVEMODE_DISABLE;
  if (HAL_TIMEx_MasterConfigSynchronization(&htim4, &sMasterConfig) != HAL_OK)
  {
    Error_Handler();
  }
  sConfigOC.OCMode = TIM_OCMODE_TIMING;
  sConfigOC.Pulse = 0;
  sConfigOC.OCPolarity = TIM_OCPOLARITY_HIGH;
  sConfigOC.OCFastMode = TIM_OCFAST_DISABLE;
  if (HAL_TIM_OC_ConfigChannel(&htim4, &sConfigOC, TIM_CHANNEL_1) != HAL_OK)
  {
    Error_Handler();
  }

}

static void MX_TIM6_Init(void)
{

  TIM_MasterConfigTypeDef sMasterConfig = {0};

  htim6.Instance = TIM6;
  htim6.Init.Prescaler = 9999;
  htim6.Init.CounterMode = TIM_COUNTERMODE_UP;
  htim6.Init.Period = 7999;
  htim6.Init.AutoReloadPreload = TIM_AUTORELOAD_PRELOAD_ENABLE;
  if (HAL_TIM_Base_Init(&htim6) != HAL_OK)
  {
    Error_Handler();
  }
  sMasterConfig.MasterOutputTrigger = TIM_TRGO_RESET;
  sMasterConfig.MasterSlaveMode = TIM_MASTERSLAVEMODE_DISABLE;
  if (HAL_TIMEx_MasterConfigSynchronization(&htim6, &sMasterConfig) != HAL_OK)
  {
    Error_Handler();
  }

}

static void MX_USART1_UART_Init(void)
{

  huart1.Instance = USART1;
  huart1.Init.BaudRate = 115200;
  huart1.Init.WordLength = UART_WORDLENGTH_8B;
  huart1.Init.StopBits = UART_STOPBITS_1;
  huart1.Init.Parity = UART_PARITY_NONE;
  huart1.Init.Mode = UART_MODE_TX_RX;
  huart1.Init.HwFlowCtl = UART_HWCONTROL_NONE;
  huart1.Init.OverSampling = UART_OVERSAMPLING_16;
  huart1.Init.OneBitSampling = UART_ONE_BIT_SAMPLE_DISABLE;
  huart1.AdvancedInit.AdvFeatureInit = UART_ADVFEATURE_NO_INIT;
  if (HAL_UART_Init(&huart1) != HAL_OK)
  {
    Error_Handler();
  }

}

static void MX_USART2_UART_Init(void)
{

  huart2.Instance = USART2;
  huart2.Init.BaudRate = 115200;
  huart2.Init.WordLength = UART_WORDLENGTH_8B;
  huart2.Init.StopBits = UART_STOPBITS_1;
  huart2.Init.Parity = UART_PARITY_NONE;
  huart2.Init.Mode = UART_MODE_TX_RX;
  huart2.Init.HwFlowCtl = UART_HWCONTROL_NONE;
  huart2.Init.OverSampling = UART_OVERSAMPLING_16;
  huart2.Init.OneBitSampling = UART_ONE_BIT_SAMPLE_DISABLE;
  huart2.AdvancedInit.AdvFeatureInit = UART_ADVFEATURE_NO_INIT;
  if (HAL_UART_Init(&huart2) != HAL_OK)
  {
    Error_Handler();
  }

}

static void MX_USART3_UART_Init(void)
{

  huart3.Instance = USART3;
  huart3.Init.BaudRate = 115200;
  huart3.Init.WordLength = UART_WORDLENGTH_8B;
  huart3.Init.StopBits = UART_STOPBITS_1;
  huart3.Init.Parity = UART_PARITY_NONE;
  huart3.Init.Mode = UART_MODE_TX_RX;
  huart3.Init.HwFlowCtl = UART_HWCONTROL_NONE;
  huart3.Init.OverSampling = UART_OVERSAMPLING_16;
  huart3.Init.OneBitSampling = UART_ONE_BIT_SAMPLE_DISABLE;
  huart3.AdvancedInit.AdvFeatureInit = UART_ADVFEATURE_NO_INIT;
  if (HAL_RS485Ex_Init(&huart3, UART_DE_POLARITY_HIGH, 0, 0) != HAL_OK)
  {
    Error_Handler();
  }

}

static void MX_DMA_Init(void)
{

  /* DMA controller clock enable */
  __HAL_RCC_DMA1_CLK_ENABLE();

  /* DMA interrupt init */
  /* DMA1_Channel1_IRQn interrupt configuration */
  HAL_NVIC_SetPriority(DMA1_Channel1_IRQn, 5, 0);
  HAL_NVIC_EnableIRQ(DMA1_Channel1_IRQn);

}

/* FMC initialization function */
static void MX_FMC_Init(void)
{

  FMC_NORSRAM_TimingTypeDef Timing = {0};

  /** Perform the SRAM1 memory initialization sequence
  */
  hsram1.Instance = FMC_NORSRAM_DEVICE;
  hsram1.Extended = FMC_NORSRAM_EXTENDED_DEVICE;
  /* hsram1.Init */
  hsram1.Init.NSBank = FMC_NORSRAM_BANK1;
  hsram1.Init.DataAddressMux = FMC_DATA_ADDRESS_MUX_DISABLE;
  hsram1.Init.MemoryType = FMC_MEMORY_TYPE_SRAM;
  hsram1.Init.MemoryDataWidth = FMC_NORSRAM_MEM_BUS_WIDTH_16;
  hsram1.Init.BurstAccessMode = FMC_BURST_ACCESS_MODE_DISABLE;
  hsram1.Init.WaitSignalPolarity = FMC_WAIT_SIGNAL_POLARITY_LOW;
  hsram1.Init.WaitSignalActive = FMC_WAIT_TIMING_BEFORE_WS;
  hsram1.Init.WriteOperation = FMC_WRITE_OPERATION_ENABLE;
  hsram1.Init.WaitSignal = FMC_WAIT_SIGNAL_DISABLE;
  hsram1.Init.ExtendedMode = FMC_EXTENDED_MODE_DISABLE;
  hsram1.Init.AsynchronousWait = FMC_ASYNCHRONOUS_WAIT_DISABLE;
  hsram1.Init.WriteBurst = FMC_WRITE_BURST_DISABLE;
  hsram1.Init.ContinuousClock = FMC_CONTINUOUS_CLOCK_SYNC_ONLY;
  hsram1.Init.WriteFifo = FMC_WRITE_FIFO_ENABLE;
  hsram1.Init.PageSize = FMC_PAGE_SIZE_NONE;
  /* Timing */
  Timing.AddressSetupTime = 0;
  Timing.AddressHoldTime = 15;
  Timing.DataSetupTime = 1;
  Timing.BusTurnAroundDuration = 3;
  Timing.CLKDivision = 16;
  Timing.DataLatency = 17;
  Timing.AccessMode = FMC_ACCESS_MODE_A;
  /* ExtTiming */

  if (HAL_SRAM_Init(&hsram1, &Timing, NULL) != HAL_OK)
  {
    Error_Handler( );
  }

}

static void MX_GPIO_Init(void)
{
  GPIO_InitTypeDef GPIO_InitStruct = {0};

  /* GPIO Ports Clock Enable */
  __HAL_RCC_GPIOE_CLK_ENABLE();
  __HAL_RCC_GPIOB_CLK_ENABLE();
  __HAL_RCC_GPIOH_CLK_ENABLE();
  __HAL_RCC_GPIOD_CLK_ENABLE();
  __HAL_RCC_GPIOA_CLK_ENABLE();
  __HAL_RCC_GPIOC_CLK_ENABLE();
  __HAL_RCC_GPIOG_CLK_ENABLE();
  HAL_PWREx_EnableVddIO2();
  __HAL_RCC_GPIOF_CLK_ENABLE();

  /*Configure GPIO pin Output Level */
  HAL_GPIO_WritePin(ACC_SA0_GPIO_Port, ACC_SA0_Pin, GPIO_PIN_RESET);

  /*Configure GPIO pin Output Level */
  HAL_GPIO_WritePin(GPIOB, FL_CS_Pin|FL_HOLD_Pin|FL_WP_Pin, GPIO_PIN_SET);

  /*Configure GPIO pin Output Level */
  HAL_GPIO_WritePin(LCD_RESET_GPIO_Port, LCD_RESET_Pin, GPIO_PIN_SET);

  /*Configure GPIO pin Output Level */
  HAL_GPIO_WritePin(GPIOC, CAN_SHDN_Pin|WIFI_EN_Pin|LIGHT_SENSOR_EN_Pin, GPIO_PIN_RESET);

  /*Configure GPIO pin Output Level */
  HAL_GPIO_WritePin(VALVE_CTRL_GPIO_Port, VALVE_CTRL_Pin, GPIO_PIN_SET);

  /*Configure GPIO pin Output Level */
  HAL_GPIO_WritePin(LCD_MODE_SET12_GPIO_Port, LCD_MODE_SET12_Pin, GPIO_PIN_RESET);

  /*Configure GPIO pin Output Level */
  HAL_GPIO_WritePin(LCD_MODE_SET0_GPIO_Port, LCD_MODE_SET0_Pin, GPIO_PIN_SET);

  /*Configure GPIO pin Output Level */
  HAL_GPIO_WritePin(FLASHLIGHT_CTRL_GPIO_Port, FLASHLIGHT_CTRL_Pin, GPIO_PIN_RESET);

  /*Configure GPIO pin Output Level */
  HAL_GPIO_WritePin(GPIOG, COM_PW_EN_Pin|RF_PW_EN_Pin|VALVE_PW_EN_Pin|WAKE_PW_EN_Pin
                          |LCD_PW_EN_Pin|DIVA_PW_EN_Pin|WIFI_PW_EN_Pin|O2_SENSOR_EN_Pin, GPIO_PIN_RESET);

  /*Configure GPIO pins : PE3 PE4 PE2 PE5
                           PE0 PE6 */
  GPIO_InitStruct.Pin = GPIO_PIN_3|GPIO_PIN_4|GPIO_PIN_2|GPIO_PIN_5
                          |GPIO_PIN_0|GPIO_PIN_6;
  GPIO_InitStruct.Mode = GPIO_MODE_ANALOG;
  GPIO_InitStruct.Pull = GPIO_NOPULL;
  HAL_GPIO_Init(GPIOE, &GPIO_InitStruct);

  /*Configure GPIO pin : ACC_SA0_Pin */
  GPIO_InitStruct.Pin = ACC_SA0_Pin;
  GPIO_InitStruct.Mode = GPIO_MODE_OUTPUT_PP;
  GPIO_InitStruct.Pull = GPIO_PULLUP;
  GPIO_InitStruct.Speed = GPIO_SPEED_FREQ_LOW;
  HAL_GPIO_Init(ACC_SA0_GPIO_Port, &GPIO_InitStruct);

  /*Configure GPIO pins : PB8 PB4 PB3 PB5
                           PB2 PB10 PB12 */
  GPIO_InitStruct.Pin = GPIO_PIN_8|GPIO_PIN_4|GPIO_PIN_3|GPIO_PIN_5
                          |GPIO_PIN_2|GPIO_PIN_10|GPIO_PIN_12;
  GPIO_InitStruct.Mode = GPIO_MODE_ANALOG;
  GPIO_InitStruct.Pull = GPIO_NOPULL;
  HAL_GPIO_Init(GPIOB, &GPIO_InitStruct);

  /*Configure GPIO pin : PH3 */
  GPIO_InitStruct.Pin = GPIO_PIN_3;
  GPIO_InitStruct.Mode = GPIO_MODE_ANALOG;
  GPIO_InitStruct.Pull = GPIO_NOPULL;
  HAL_GPIO_Init(GPIOH, &GPIO_InitStruct);

  /*Configure GPIO pins : PA15 PA7 */
  GPIO_InitStruct.Pin = GPIO_PIN_15|GPIO_PIN_7;
  GPIO_InitStruct.Mode = GPIO_MODE_ANALOG;
  GPIO_InitStruct.Pull = GPIO_NOPULL;
  HAL_GPIO_Init(GPIOA, &GPIO_InitStruct);

  /*Configure GPIO pins : FL_CS_Pin FL_HOLD_Pin FL_WP_Pin */
  GPIO_InitStruct.Pin = FL_CS_Pin|FL_HOLD_Pin|FL_WP_Pin;
  GPIO_InitStruct.Mode = GPIO_MODE_OUTPUT_PP;
  GPIO_InitStruct.Pull = GPIO_PULLUP;
  GPIO_InitStruct.Speed = GPIO_SPEED_FREQ_LOW;
  HAL_GPIO_Init(GPIOB, &GPIO_InitStruct);

  /*Configure GPIO pin : LCD_RESET_Pin */
  GPIO_InitStruct.Pin = LCD_RESET_Pin;
  GPIO_InitStruct.Mode = GPIO_MODE_OUTPUT_PP;
  GPIO_InitStruct.Pull = GPIO_PULLUP;
  GPIO_InitStruct.Speed = GPIO_SPEED_FREQ_LOW;
  HAL_GPIO_Init(LCD_RESET_GPIO_Port, &GPIO_InitStruct);

  /*Configure GPIO pins : CAN_SHDN_Pin WIFI_EN_Pin LIGHT_SENSOR_EN_Pin */
  GPIO_InitStruct.Pin = CAN_SHDN_Pin|WIFI_EN_Pin|LIGHT_SENSOR_EN_Pin;
  GPIO_InitStruct.Mode = GPIO_MODE_OUTPUT_PP;
  GPIO_InitStruct.Pull = GPIO_PULLUP;
  GPIO_InitStruct.Speed = GPIO_SPEED_FREQ_LOW;
  HAL_GPIO_Init(GPIOC, &GPIO_InitStruct);

  /*Configure GPIO pins : PC13 PC9 PC8 PC7 */
  GPIO_InitStruct.Pin = GPIO_PIN_13|GPIO_PIN_9|GPIO_PIN_8|GPIO_PIN_7;
  GPIO_InitStruct.Mode = GPIO_MODE_ANALOG;
  GPIO_InitStruct.Pull = GPIO_NOPULL;
  HAL_GPIO_Init(GPIOC, &GPIO_InitStruct);

  /*Configure GPIO pin : VALVE_CTRL_Pin */
  GPIO_InitStruct.Pin = VALVE_CTRL_Pin;
  GPIO_InitStruct.Mode = GPIO_MODE_OUTPUT_PP;
  GPIO_InitStruct.Pull = GPIO_PULLUP;
  GPIO_InitStruct.Speed = GPIO_SPEED_FREQ_VERY_HIGH;
  HAL_GPIO_Init(VALVE_CTRL_GPIO_Port, &GPIO_InitStruct);

  /*Configure GPIO pin : LCD_MODE_SET12_Pin */
  GPIO_InitStruct.Pin = LCD_MODE_SET12_Pin;
  GPIO_InitStruct.Mode = GPIO_MODE_OUTPUT_PP;
  GPIO_InitStruct.Pull = GPIO_PULLDOWN;
  GPIO_InitStruct.Speed = GPIO_SPEED_FREQ_LOW;
  HAL_GPIO_Init(LCD_MODE_SET12_GPIO_Port, &GPIO_InitStruct);

  /*Configure GPIO pin : LCD_MODE_SET0_Pin */
  GPIO_InitStruct.Pin = LCD_MODE_SET0_Pin;
  GPIO_InitStruct.Mode = GPIO_MODE_OUTPUT_PP;
  GPIO_InitStruct.Pull = GPIO_PULLUP;
  GPIO_InitStruct.Speed = GPIO_SPEED_FREQ_LOW;
  HAL_GPIO_Init(LCD_MODE_SET0_GPIO_Port, &GPIO_InitStruct);

  /*Configure GPIO pins : PG12 PG10 PG9 PG11
                           PG7 PG8 */
  GPIO_InitStruct.Pin = GPIO_PIN_12|GPIO_PIN_10|GPIO_PIN_9|GPIO_PIN_11
                          |GPIO_PIN_7|GPIO_PIN_8;
  GPIO_InitStruct.Mode = GPIO_MODE_ANALOG;
  GPIO_InitStruct.Pull = GPIO_NOPULL;
  HAL_GPIO_Init(GPIOG, &GPIO_InitStruct);

  /*Configure GPIO pin : FLASHLIGHT_CTRL_Pin */
  GPIO_InitStruct.Pin = FLASHLIGHT_CTRL_Pin;
  GPIO_InitStruct.Mode = GPIO_MODE_OUTPUT_PP;
  GPIO_InitStruct.Pull = GPIO_NOPULL;
  GPIO_InitStruct.Speed = GPIO_SPEED_FREQ_LOW;
  HAL_GPIO_Init(FLASHLIGHT_CTRL_GPIO_Port, &GPIO_InitStruct);

  /*Configure GPIO pins : PF3 PF4 PF5 PF12
                           PF14 PF15 PF11 PF13 */
  GPIO_InitStruct.Pin = GPIO_PIN_3|GPIO_PIN_4|GPIO_PIN_5|GPIO_PIN_12
                          |GPIO_PIN_14|GPIO_PIN_15|GPIO_PIN_11|GPIO_PIN_13;
  GPIO_InitStruct.Mode = GPIO_MODE_ANALOG;
  GPIO_InitStruct.Pull = GPIO_NOPULL;
  HAL_GPIO_Init(GPIOF, &GPIO_InitStruct);

  /*Configure GPIO pins : COM_PW_EN_Pin RF_PW_EN_Pin VALVE_PW_EN_Pin WAKE_PW_EN_Pin
                           LCD_PW_EN_Pin DIVA_PW_EN_Pin WIFI_PW_EN_Pin O2_SENSOR_EN_Pin */
  GPIO_InitStruct.Pin = COM_PW_EN_Pin|RF_PW_EN_Pin|VALVE_PW_EN_Pin|WAKE_PW_EN_Pin
                          |LCD_PW_EN_Pin|DIVA_PW_EN_Pin|WIFI_PW_EN_Pin|O2_SENSOR_EN_Pin;
  GPIO_InitStruct.Mode = GPIO_MODE_OUTPUT_PP;
  GPIO_InitStruct.Pull = GPIO_NOPULL;
  GPIO_InitStruct.Speed = GPIO_SPEED_FREQ_LOW;
  HAL_GPIO_Init(GPIOG, &GPIO_InitStruct);

  /*Configure GPIO pins : PD13 PD12 PD11 */
  GPIO_InitStruct.Pin = GPIO_PIN_13|GPIO_PIN_12|GPIO_PIN_11;
  GPIO_InitStruct.Mode = GPIO_MODE_ANALOG;
  GPIO_InitStruct.Pull = GPIO_NOPULL;
  HAL_GPIO_Init(GPIOD, &GPIO_InitStruct);

  /*Configure GPIO pins : WET_SW_Pin MAIN_SW_Pin TAP_SW_Pin */
  GPIO_InitStruct.Pin = WET_SW_Pin|MAIN_SW_Pin|TAP_SW_Pin;
  GPIO_InitStruct.Mode = GPIO_MODE_INPUT;
  GPIO_InitStruct.Pull = GPIO_NOPULL;
  HAL_GPIO_Init(GPIOA, &GPIO_InitStruct);

}

void StartDefaultTask(void *argument)
{
  for(;;)
  {
    osDelay(1);
  }
}

void HAL_TIM_PeriodElapsedCallback(TIM_HandleTypeDef *htim)
{
  /* USER CODE BEGIN Callback 0 */
  if (htim == &htim6)
  {
    main_process_1sec_event();
  }
  /* USER CODE END Callback 0 */
  if (htim->Instance == TIM16)
  {
    HAL_IncTick();
  }
}

void Error_Handler(void)
{
  __disable_irq();
  while (1)
  {
  }
}
